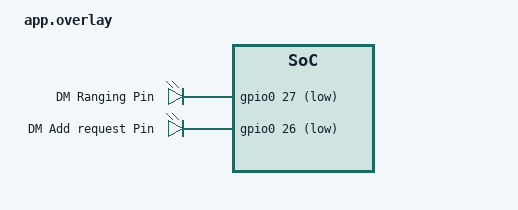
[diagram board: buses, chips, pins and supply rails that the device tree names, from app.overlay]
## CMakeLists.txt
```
#
# Copyright (c) 2021 Nordic Semiconductor
#
# SPDX-License-Identifier: LicenseRef-Nordic-5-Clause
#
cmake_minimum_required(VERSION 3.20)

find_package(Zephyr REQUIRED HINTS $ENV{ZEPHYR_BASE})
project(nrf_dm)

# NORDIC SDK APP START
target_sources(app PRIVATE
  src/main.c
  src/pwm_led.c
  src/peer.c
  src/service.c
  )
# NORDIC SDK APP END

zephyr_library_include_directories(${CMAKE_CURRENT_SOURCE_DIR})
```

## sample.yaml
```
sample:
  description: nRF Distance Measurement sample
  name: Distance measurement sample
common:
  tags:
    - bluetooth
    - ci_build
    - sysbuild
    - ci_samples_bluetooth
tests:
  sample.bluetooth.nrf_dm.timeslot:
    sysbuild: true
    build_only: true
    extra_configs:
      - CONFIG_DM_HIGH_PRECISION_CALC=n
    integration_platforms:
      - nrf5340dk/nrf5340/cpuapp
    platform_allow:
      - nrf5340dk/nrf5340/cpuapp
  sample.bluetooth.nrf_dm.timeslot.high_precision:
    sysbuild: true
    build_only: true
    extra_configs:
      - CONFIG_DM_HIGH_PRECISION_CALC=y
    integration_platforms:
      - nrf5340dk/nrf5340/cpuapp
    platform_allow:
      - nrf5340dk/nrf5340/cpuapp
```

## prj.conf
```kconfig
#
# Copyright (c) 2021 Nordic Semiconductor ASA
#
# SPDX-License-Identifier: LicenseRef-Nordic-5-Clause
#

# BT
CONFIG_BT=y

CONFIG_BT_CENTRAL=y
CONFIG_BT_PERIPHERAL=y

CONFIG_BT_SCAN=y
CONFIG_BT_SCAN_FILTER_ENABLE=y
CONFIG_BT_SCAN_NAME_CNT=1
CONFIG_BT_SCAN_MANUFACTURER_DATA_CNT=1
CONFIG_BT_SCAN_WITH_IDENTITY=y
CONFIG_BT_ID_MAX=1

CONFIG_BT_EXT_ADV=y

CONFIG_BT_DEVICE_NAME="nRF_DM"
CONFIG_BT_DDFS=y

# Distance Measurement
CONFIG_DM_MODULE=y

# Ineffective here: unsatisfied dependency HAS_MPSL_SUPPORT, so MPSL stays n.
# CONFIG_MPSL=y
CONFIG_MPSL_TIMESLOT_SESSION_COUNT=1

CONFIG_DM_MODULE_LOG_LEVEL_DBG=n
CONFIG_DM_GPIO_DEBUG=y
CONFIG_PWM=y

CONFIG_NCS_SAMPLES_DEFAULTS=y
CONFIG_DK_LIBRARY=y

CONFIG_DM_HIGH_PRECISION_CALC=y
```

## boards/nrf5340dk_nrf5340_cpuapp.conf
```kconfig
#
# Copyright (c) 2022 Nordic Semiconductor
#
# SPDX-License-Identifier: LicenseRef-Nordic-5-Clause
#

# Distance Measurement
CONFIG_DM_MODULE_RPC=y
CONFIG_DM_MODULE_RPC_CLIENT=y

CONFIG_TEST_RANDOM_GENERATOR=y

# NRF RPC
CONFIG_NRF_RPC_THREAD_POOL_SIZE=2

# SYSTEM WORKQUEUE
CONFIG_SYSTEM_WORKQUEUE_STACK_SIZE=3072
```

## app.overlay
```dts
/*
 * Copyright (c) 2023 Nordic Semiconductor ASA
 *
 * SPDX-License-Identifier: LicenseRef-Nordic-5-Clause
 */

/ {
	/* The timer instance to use. */
	chosen {
		ncs,dm-timer = &timer2;
	};

	/* The selected pins will be used by Distance Measurement module for debug purposes. */
	dm_gpio {
		compatible = "gpio-leds";

		dm_ranging: dm-ranging {
			gpios = <&gpio0 27 GPIO_ACTIVE_LOW>;
			label = "DM Ranging Pin";
		};

		dm_add_request: dm-add-request {
			gpios = <&gpio0 26 GPIO_ACTIVE_LOW>;
			label = "DM Add request Pin";
		};
	};
};
```

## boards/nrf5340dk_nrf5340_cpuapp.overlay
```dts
/*
 * Copyright (c) 2022 Nordic Semiconductor ASA
 *
 * SPDX-License-Identifier: LicenseRef-Nordic-5-Clause
 */

/* Enable pin forwarding to network core. The selected pins will be used by
 * Distance Measurement module for debug purposes.
 *
 * Note: Pay attention to assign the same GPIO pins as those provide in network core DTS overlay.
 */
&gpio_fwd {
	compatible = "nordic,nrf-gpio-forwarder";

	dm-gpio-if {
		gpios = <&gpio0 26 0>,
			<&gpio0 27 0>;
	};
};
```

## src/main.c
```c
/*
 * Copyright (c) 2021 Nordic Semiconductor ASA
 *
 * SPDX-License-Identifier: LicenseRef-Nordic-5-Clause
 */

/** @file
 *  @brief Nordic Distance Measurement sample
 */

#include <stdint.h>
#include <zephyr/kernel.h>
#include <zephyr/sys/printk.h>
#include <zephyr/sys/byteorder.h>

#include <zephyr/bluetooth/bluetooth.h>
#include <bluetooth/scan.h>
#include <bluetooth/services/ddfs.h>

#include <dk_buttons_and_leds.h>

#include <dm.h>
#include "peer.h"
#include "service.h"

#define DEVICE_NAME             CONFIG_BT_DEVICE_NAME
#define DEVICE_NAME_LEN         (sizeof(DEVICE_NAME) - 1)

#define RUN_STATUS_LED          DK_LED2
#define CON_STATUS_LED          DK_LED3
#define RUN_LED_BLINK_INTERVAL  1000

#define SUPPORT_DM_CODE         0xFF55AA5A

struct adv_mfg_data {
	uint16_t company_code;	    /* Company Identifier Code. */
	uint32_t support_dm_code;   /* To identify the device that supports distance measurement. */
	uint32_t rng_seed;          /* Random seed used for generating hopping patterns. */
} __packed;

static struct adv_mfg_data mfg_data;
struct bt_le_adv_param adv_param_conn =
	BT_LE_ADV_PARAM_INIT(BT_LE_ADV_OPT_CONN |
			     BT_LE_ADV_OPT_NOTIFY_SCAN_REQ,
			     BT_GAP_ADV_FAST_INT_MIN_2,
			     BT_GAP_ADV_FAST_INT_MAX_2,
			     NULL);

struct bt_le_adv_param adv_param_noconn =
	BT_LE_ADV_PARAM_INIT(BT_LE_ADV_OPT_USE_IDENTITY |
			     BT_LE_ADV_OPT_SCANNABLE |
			     BT_LE_ADV_OPT_NOTIFY_SCAN_REQ,
			     BT_GAP_ADV_FAST_INT_MIN_2,
			     BT_GAP_ADV_FAST_INT_MAX_2,
			     NULL);


struct bt_le_adv_param *adv_param = &adv_param_conn;

static const struct bt_data ad[] = {
	BT_DATA_BYTES(BT_DATA_FLAGS, (BT_LE_AD_GENERAL | BT_LE_AD_NO_BREDR)),
	BT_DATA(BT_DATA_NAME_COMPLETE, DEVICE_NAME, DEVICE_NAME_LEN),
};

static const struct bt_data sd[] = {
	BT_DATA(BT_DATA_MANUFACTURER_DATA, (unsigned char *)&mfg_data, sizeof(mfg_data)),
	BT_DATA_BYTES(BT_DATA_UUID128_ALL, BT_UUID_DDFS_VAL),
};

static struct bt_le_scan_param scan_param = {
	.type     = BT_LE_SCAN_TYPE_ACTIVE,
	.interval = BT_GAP_SCAN_FAST_INTERVAL,
	.window   = BT_GAP_SCAN_FAST_WINDOW,
	.options  = BT_LE_SCAN_OPT_NONE,
	.timeout  = 0,
};

static struct bt_scan_init_param scan_init = {
	.connect_if_match = 0,
	.scan_param = &scan_param,
	.conn_param = NULL
};

static uint32_t scanner_random_share;

static struct bt_le_ext_adv *adv;
static void adv_work_handle(struct k_work *item);
static K_WORK_DEFINE(adv_work, adv_work_handle);
static void adv_update_data(void);
static uint32_t scanner_addr_to_random_share(const bt_addr_t *p_scanner_addr);
static uint32_t get_id_addr_random_share(void);

static struct bt_scan_manufacturer_data scan_mfg_data = {
	.data = (unsigned char *)&mfg_data,
	.data_len = sizeof(mfg_data.company_code) + sizeof(mfg_data.support_dm_code),
};

static bool data_cb(struct bt_data *data, void *user_data)
{
	struct adv_mfg_data *recv_mfg_data;
	struct dm_request req;

	switch (data->type) {
	case BT_DATA_MANUFACTURER_DATA:
		if (sizeof(struct adv_mfg_data) == data->data_len) {
			recv_mfg_data = (struct adv_mfg_data *)data->data;

			bt_addr_le_copy(&req.bt_addr, user_data);
			req.role = DM_ROLE_INITIATOR;
			req.ranging_mode = peer_ranging_mode_get();
			/* We need to make sure that we only initiate a ranging to a single peer.
			 * A scan response that is received by this device can be received by
			 * multiple other devices which can all start a ranging at the same time
			 * as a consequence. To prevent this, we need to make sure that we set a
			 * per-peer random as the random seed. This helps the ranging library to
			 * avoid interference from other devices trying to range at the same time.
			 *
			 * This means that the initiator and the reflector need to set the same
			 * value for the random seed.
			 */
			req.rng_seed =
				sys_le32_to_cpu(recv_mfg_data->rng_seed) + scanner_random_share;
			req.start_delay_us = 0;
			req.extra_window_time_us = 0;

			dm_request_add(&req);
		}
		return false;
	default:
		return true;
	}
}

static uint32_t get_id_addr_random_share(void)
{
	bt_addr_le_t addrs[CONFIG_BT_ID_MAX];
	size_t count = CONFIG_BT_ID_MAX;

	bt_id_get(addrs, &count);

	__ASSERT(count == 1, "The sample assumes a single ID addr");

	return scanner_addr_to_random_share(&addrs[0].a);
}

static uint32_t scanner_addr_to_random_share(const bt_addr_t *p_scanner_addr)
{
	return (p_scanner_addr->val[0] | p_scanner_addr->val[1] << 8 |
		p_scanner_addr->val[2] << 16 | p_scanner_addr->val[3] << 24) +
	       (p_scanner_addr->val[4] | p_scanner_addr->val[5] << 8);
}

static void scan_filter_match(struct bt_scan_device_info *device_info,
			      struct bt_scan_filter_match *filter_match,
			      bool connectable)
{
	bt_addr_le_t addr;

	bt_addr_le_copy(&addr, device_info->recv_info->addr);
	peer_supported_add(device_info->recv_info->addr);
	bt_data_parse(device_info->adv_data, data_cb, &addr);
}

BT_SCAN_CB_INIT(scan_cb, scan_filter_match, NULL, NULL, NULL);

static void adv_scanned_cb(struct bt_le_ext_adv *adv,
			struct bt_le_ext_adv_scanned_info *info)
{
	struct dm_request req;

	if (peer_supported_test(info->addr)) {
		bt_addr_le_copy(&req.bt_addr, info->addr);
		req.role = DM_ROLE_REFLECTOR;
		req.ranging_mode = peer_ranging_mode_get();

		/* We need to make sure that we only initiate a ranging to a single peer.
		 * A scan response from this device can be received by multiple peers which can
		 * all start a ranging at the same time as a consequence. To prevent this,
		 * we need to make sure that we set a per-peer random as the random seed.
		 * This helps the ranging library to avoid interference from other devices
		 * trying to range at the same time.
		 *
		 * This means that the initiator and the reflector need to set the same value
		 * for the random seed.
		 */
		req.rng_seed = peer_rng_seed_get() + scanner_addr_to_random_share(&info->addr->a);
		req.start_delay_us = 0;
		req.extra_window_time_us = 0;

		dm_request_add(&req);
		adv_update_data();
	}
}

const static struct bt_le_ext_adv_cb adv_cb = {
	.scanned = adv_scanned_cb,
};

static void adv_update_data(void)
{
	int err;

	if (!adv) {
		return;
	}
	mfg_data.rng_seed = peer_rng_seed_prepare();
	err = bt_le_ext_adv_set_data(adv, ad, ARRAY_SIZE(ad), sd, ARRAY_SIZE(sd));
	if (err) {
		printk("Failed setting adv data (err %d)\n", err);
	}
}

static int adv_start(void)
{
	int err;
	struct bt_le_ext_adv_start_param ext_adv_start_param = {0};

	if (adv) {
		err = bt_le_ext_adv_stop(adv);
		if (err) {
			printk("Failed to stop extended advertising  (err %d)\n", err);
			return err;
		}
			err = bt_le_ext_adv_delete(adv);
		if (err) {
			printk("Failed to delete advertising set  (err %d)\n", err);
			return err;
		}
	}

	err = bt_le_ext_adv_create(adv_param, &adv_cb, &adv);
	if (err) {
		printk("Failed to create advertising set (err %d)\n", err);
		return err;
	}

	err = bt_le_ext_adv_set_data(adv, ad, ARRAY_SIZE(ad), sd, ARRAY_SIZE(sd));
	if (err) {
		printk("Failed setting adv data (err %d)\n", err);
		return err;
	}

	err = bt_le_ext_adv_start(adv, &ext_adv_start_param);
	if (err) {
		printk("Failed to start extended advertising  (err %d)\n", err);
		return err;
	}

	return err;
}

static int scan_start(void)
{
	int err;

	bt_scan_init(&scan_init);
	bt_scan_cb_register(&scan_cb);

	err = bt_scan_filter_add(BT_SCAN_FILTER_TYPE_MANUFACTURER_DATA, &scan_mfg_data);
	if (err) {
		printk("Scanning filters cannot be set (err %d)\n", err);
		return err;
	}

	err = bt_scan_filter_enable(BT_SCAN_MANUFACTURER_DATA_FILTER, false);
	if (err) {
		printk("Filters cannot be turned on (err %d)\n", err);
		return err;
	}

	scanner_random_share = get_id_addr_random_share();

	err = bt_scan_start(BT_SCAN_TYPE_SCAN_ACTIVE);
	if (err) {
		printk("Scanning failed to start (err %d)\n", err);
		return err;
	}

	return err;
}

static void adv_work_handle(struct k_work *item)
{
	adv_start();
}

static void connected(struct bt_conn *conn, uint8_t conn_err)
{
	adv_param = &adv_param_noconn;
	k_work_submit(&adv_work);

	dk_set_led_on(CON_STATUS_LED);
}

static void disconnected(struct bt_conn *conn, uint8_t reason)
{
	adv_param = &adv_param_conn;
	k_work_submit(&adv_work);

	dk_set_led_off(CON_STATUS_LED);
}

BT_CONN_CB_DEFINE(conn_callbacks) = {
	.connected = connected,
	.disconnected = disconnected,
};

static int bt_sync_init(void)
{
	/* Synchronisation is based on advertising and scanning modes.
	 * It occurs when SCAN_REQ and SCAN_RESP packets are exchanged.
	 */

	int err;

	printk("DM Bluetooth LE Synchronization initialization\n");

	mfg_data.company_code = sys_cpu_to_le16(CONFIG_BT_COMPANY_ID_NORDIC);
	mfg_data.support_dm_code = sys_cpu_to_le32(SUPPORT_DM_CODE);
	mfg_data.rng_seed = sys_cpu_to_le32(peer_rng_seed_prepare());

	err = adv_start();
	if (err) {
		printk("Failed to start advertising (err %d)\n", err);
		return err;
	}

	err = scan_start();
	if (err) {
		printk("Failed to start scanning (err %d)\n", err);
	}

	return err;
}

static void data_ready(struct dm_result *result)
{
	if (result->status) {
		peer_update(result);
	}
}

static struct dm_cb dm_cb = {
	.data_ready = data_ready,
};

int main(void)
{
	int err;
	uint32_t blink_status = 0;
	struct dm_init_param init_param;

	printk("Starting Distance Measurement sample\n");

	err = dk_leds_init();
	if (err) {
		printk("LEDs init failed (err %d)\n", err);
		return 0;
	}

	err = peer_init();
	if (err) {
		printk("Peer init failed (err %d)\n", err);
		return 0;
	}

	init_param.cb = &dm_cb;

	err = dm_init(&init_param);
	if (err) {
		printk("Distance measurement init failed (err %d)\n", err);
		return 0;
	}

	err = service_ddfs_init();
	if (err) {
		printk("DDF Service init failed (err %d)\n", err);
		return 0;
	}

	err = bt_enable(NULL);
	if (err) {
		printk("Bluetooth init failed (err %d)\n", err);
		return 0;
	}

	err = bt_sync_init();
	if (err) {
		printk("Synchronisation init failed (err %d)\n", err);
		return 0;
	}

	for (;;) {
		dk_set_led(RUN_STATUS_LED, (++blink_status) % 2);
		k_sleep(K_MSEC(RUN_LED_BLINK_INTERVAL));
		service_azimuth_elevation_simulation();
	}
}
```

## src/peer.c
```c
/*
 * Copyright (c) 2021 Nordic Semiconductor ASA
 *
 * SPDX-License-Identifier: LicenseRef-Nordic-5-Clause
 */

#include <zephyr/kernel.h>
#include <zephyr/random/random.h>

#include <math.h>

#include "peer.h"
#include "pwm_led.h"
#include "service.h"

#define PEER_MAX                8   /* Maximum number of tracked peer devices. */

#define STACKSIZE               1024
#define PEER_THREAD_PRIORITY    K_LOWEST_APPLICATION_THREAD_PRIO

#define PEER_TIMEOUT_STEP_MS    500
#define PEER_TIMEOUT_INIT_MS    10000

#define DISTANCE_MAX_LED        50   /* from 0 to DISTANCE_MAX_LED [decimeter] -
				      * the distance range which is indicated by the PWM LED
				      */
#define DEFAULT_RANGING_MODE    DM_RANGING_MODE_MCPD

static void timeout_handler(struct k_timer *timer_id);
static K_TIMER_DEFINE(timer, timeout_handler, NULL);

struct peer_entry {
	sys_snode_t node;
	bt_addr_le_t bt_addr;
	struct dm_result result;
	uint16_t timeout_ms;
};

static struct peer_entry *closest_peer;
static uint32_t rng_seed;
static enum dm_ranging_mode ranging_mode = DEFAULT_RANGING_MODE;

K_MSGQ_DEFINE(result_msgq, sizeof(struct dm_result), 16, 4);

static K_HEAP_DEFINE(peer_heap, PEER_MAX * sizeof(struct peer_entry));
static sys_slist_t peer_list = SYS_SLIST_STATIC_INIT(&peer_list);

static K_MUTEX_DEFINE(list_mtx);

static void list_lock(void)
{
	k_mutex_lock(&list_mtx, K_FOREVER);
}

static void list_unlock(void)
{
	k_mutex_unlock(&list_mtx);
}

static struct peer_entry *mcpd_min_peer_result(struct peer_entry *a, struct peer_entry *b)
{
	if (!a && !b) {
		return NULL;
	} else if (!a && b) {
		return b->result.ranging_mode == DM_RANGING_MODE_MCPD ? b : NULL;
	} else if (a && !b) {
		return a->result.ranging_mode == DM_RANGING_MODE_MCPD ? a : NULL;
	} else if (a->result.ranging_mode == DM_RANGING_MODE_RTT &&
		   b->result.ranging_mode == DM_RANGING_MODE_RTT) {
		return NULL;
	} else if (a->result.ranging_mode == DM_RANGING_MODE_RTT &&
		   b->result.ranging_mode == DM_RANGING_MODE_MCPD) {
		return b;
	} else if (a->result.ranging_mode == DM_RANGING_MODE_MCPD &&
		   b->result.ranging_mode == DM_RANGING_MODE_RTT){
		return a;
	}

#ifdef CONFIG_DM_HIGH_PRECISION_CALC
	float dist_a = !isnan(a->result.dist_estimates.mcpd.high_precision) ?
		  a->result.dist_estimates.mcpd.high_precision : a->result.dist_estimates.mcpd.best;
	float dist_b = !isnan(b->result.dist_estimates.mcpd.high_precision) ?
		  b->result.dist_estimates.mcpd.high_precision : b->result.dist_estimates.mcpd.best;

	if (dist_a < dist_b) {
		return a;
	}
	return b;
#else
	if (a->result.dist_estimates.mcpd.best < b->result.dist_estimates.mcpd.best) {
		return a;
	}
	return b;
#endif
}

static struct peer_entry *peer_find_closest(void)
{
	struct peer_entry *closest_peer, *item;
	sys_snode_t *node, *tmp;

	closest_peer = SYS_SLIST_PEEK_HEAD_CONTAINER(&peer_list, closest_peer, node);
	if (!closest_peer) {
		return NULL;
	}

	SYS_SLIST_FOR_EACH_NODE_SAFE(&peer_list, node, tmp) {
		item = CONTAINER_OF(node, struct peer_entry, node);
		closest_peer = mcpd_min_peer_result(closest_peer, item);
	}

	return closest_peer;
}

struct peer_entry *peer_find(const bt_addr_le_t *peer)
{
	if (!peer) {
		return NULL;
	}

	sys_snode_t *node, *tmp;
	struct peer_entry *item;

	SYS_SLIST_FOR_EACH_NODE_SAFE(&peer_list, node, tmp) {
		item = CONTAINER_OF(node, struct peer_entry, node);
		if (bt_addr_le_cmp(&item->bt_addr, peer) == 0) {
			return item;
		}
	}

	return NULL;
}

static void ble_notification(const struct peer_entry *peer)
{
	service_distance_measurement_update(&peer->bt_addr, &peer->result);
}

static void led_notification(const struct peer_entry *peer)
{
	if (!peer) {
		pwm_led_set(0);
		return;
	}

	float res;

	if (peer->result.ranging_mode == DM_RANGING_MODE_RTT) {
		res = peer->result.dist_estimates.rtt.rtt;
	} else {
#ifdef CONFIG_DM_HIGH_PRECISION_CALC
		res = peer->result.dist_estimates.mcpd.high_precision;
		res = isnan(res) ? peer->result.dist_estimates.mcpd.best : res;
#else
		res = peer->result.dist_estimates.mcpd.best;
#endif
	}

	res = (res < 0 ? 0 : res) * 10;
	if (res > DISTANCE_MAX_LED) {
		pwm_led_set(0);
	} else {
		pwm_led_set((UINT16_MAX/DISTANCE_MAX_LED * res * (-1)) + UINT16_MAX);
	}
}

static void print_result(struct dm_result *result)
{
	if (!result) {
		return;
	}

	const char *quality[DM_QUALITY_NONE + 1] = {"ok", "poor", "do not use", "crc fail", "none"};
	char addr[BT_ADDR_LE_STR_LEN];

	bt_addr_le_to_str(&result->bt_addr, addr, sizeof(addr));

	printk("\nMeasurement result:\n");
	printk("\tAddr: %s\n", addr);
	printk("\tQuality: %s\n", quality[result->quality]);

	printk("\tDistance estimates: ");
	if (result->ranging_mode == DM_RANGING_MODE_RTT) {
		printk("rtt: rtt=%.2f\n", (double)result->dist_estimates.rtt.rtt);
	} else {
#ifdef CONFIG_DM_HIGH_PRECISION_CALC
		printk("mcpd: high_precision=%.2f ifft=%.2f phase_slope=%.2f "
			"rssi_openspace=%.2f best=%.2f\n",
			(double)result->dist_estimates.mcpd.high_precision,
			(double)result->dist_estimates.mcpd.ifft,
			(double)result->dist_estimates.mcpd.phase_slope,
			(double)result->dist_estimates.mcpd.rssi_openspace,
			(double)result->dist_estimates.mcpd.best);
#else
		printk("mcpd: ifft=%.2f phase_slope=%.2f rssi_openspace=%.2f best=%.2f\n",
			(double)result->dist_estimates.mcpd.ifft,
			(double)result->dist_estimates.mcpd.phase_slope,
			(double)result->dist_estimates.mcpd.rssi_openspace,
			(double)result->dist_estimates.mcpd.best);
#endif
	}
}

static void timeout_handler(struct k_timer *timer_id)
{
	sys_snode_t *node, *tmp;
	struct peer_entry *item;

	SYS_SLIST_FOR_EACH_NODE_SAFE(&peer_list, node, tmp) {
		item = CONTAINER_OF(node, struct peer_entry, node);
		if (item->timeout_ms > PEER_TIMEOUT_STEP_MS) {
			item->timeout_ms -= PEER_TIMEOUT_STEP_MS;
		} else {
			sys_slist_remove(&peer_list, NULL, node);
			k_heap_free(&peer_heap, item);
			closest_peer = peer_find_closest();

			led_notification(closest_peer);
		}
	}
}

static void peer_thread(void)
{
	struct dm_result result;

	while (1) {
		if (k_msgq_get(&result_msgq, &result, K_FOREVER) == 0) {
			struct peer_entry *peer;

			peer = peer_find(&result.bt_addr);
			if (!peer) {
				continue;
			}

			memcpy(&peer->result, &result, sizeof(peer->result));
			peer->timeout_ms = PEER_TIMEOUT_INIT_MS;
			print_result(&peer->result);

			closest_peer = mcpd_min_peer_result(closest_peer, peer);

			led_notification(closest_peer);
			ble_notification(peer);
		}
	}
}

void peer_ranging_mode_set(enum dm_ranging_mode mode)
{
	ranging_mode = mode;
}

enum dm_ranging_mode peer_ranging_mode_get(void)
{
	return ranging_mode;
}

uint32_t peer_rng_seed_prepare(void)
{
	rng_seed = sys_rand32_get();
	return rng_seed;
}

uint32_t peer_rng_seed_get(void)
{
	return rng_seed;
}

bool peer_supported_test(const bt_addr_le_t *peer)
{
	sys_snode_t *node, *tmp;
	struct peer_entry *item;

	SYS_SLIST_FOR_EACH_NODE_SAFE(&peer_list, node, tmp) {
		item = CONTAINER_OF(node, struct peer_entry, node);
		if (bt_addr_le_cmp(&item->bt_addr, peer) == 0) {
			return true;
		}
	}

	return false;
}

int peer_supported_add(const bt_addr_le_t *peer)
{
	struct peer_entry *item;

	if (peer_supported_test(peer)) {
		return 0;
	}

	item = k_heap_alloc(&peer_heap, sizeof(struct peer_entry), K_NO_WAIT);
	if (!item) {
		return -ENOMEM;
	}

	item->timeout_ms = PEER_TIMEOUT_INIT_MS;
	bt_addr_le_copy(&item->bt_addr, peer);
	list_lock();
	sys_slist_append(&peer_list, &item->node);
	list_unlock();

	return 0;
}

void peer_update(struct dm_result *result)
{
	k_msgq_put(&result_msgq, result, K_NO_WAIT);
}

int peer_init(void)
{
	int err;

	k_timer_start(&timer, K_NO_WAIT, K_MSEC(PEER_TIMEOUT_STEP_MS));

	err = pwm_led_init();
	if (err) {
		printk("PWM LED init failed (err %d)\n", err);
		return err;
	}

	return 0;
}

K_THREAD_DEFINE(peer_consumer_thred_id, STACKSIZE, peer_thread,
		NULL, NULL, NULL, PEER_THREAD_PRIORITY, 0, 0);
```

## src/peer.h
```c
/*
 * Copyright (c) 2021 Nordic Semiconductor ASA
 *
 * SPDX-License-Identifier: LicenseRef-Nordic-5-Clause
 */

#ifndef PEER_H_
#define PEER_H_

#ifdef __cplusplus
extern "C" {
#endif

#include <zephyr/kernel.h>
#include <zephyr/bluetooth/addr.h>
#include <dm.h>

/** @brief Testing if the peer is supported.
 *
 *  @param peer Bluetooth LE Device Address.
 *
 *  @retval /a true peer is supported.
 *          /a false peer is not supported.
 */
bool peer_supported_test(const bt_addr_le_t *peer);

/** @brief Add a new supported peer.
 *
 *  @param peer Bluetooth LE Device Address.
 *
 *  @retval 0 if the operation was successful, otherwise a (negative) error code.
 */
int peer_supported_add(const bt_addr_le_t *peer);

/** @brief Set a new Distance Measurement ranging mode.
 *
 *  @param mode Ranging mode.
 */
void peer_ranging_mode_set(enum dm_ranging_mode mode);

/** @brief Get the current ranging mode.
 *
 *  @param None
 *
 *  @retval Ranging mode value.
 */
enum dm_ranging_mode peer_ranging_mode_get(void);

/** @brief Prepare and get a random seed.
 *
 *  @retval Random seed value.
 */
uint32_t peer_rng_seed_prepare(void);

/** @brief Get the current random seed.
 *
 *  @retval Random seed value.
 */
uint32_t peer_rng_seed_get(void);

/** @brief Initialize the peer management module.
 *
 *  @param None
 *
 *  @retval 0 if the operation was successful, otherwise a (negative) error code.
 */
int peer_init(void);

/** @brief Peer measurement update.
 *
 *  @param result Measurement structure.
 */
void peer_update(struct dm_result *result);


#ifdef __cplusplus
}
#endif

#endif /* PEER_H_ */
```

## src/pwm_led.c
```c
/*
 * Copyright (c) 2021 Nordic Semiconductor ASA
 *
 * SPDX-License-Identifier: LicenseRef-Nordic-5-Clause
 */

#include "pwm_led.h"
#include <nrfx.h>
#include <nrfx_gpiote.h>
#include <zephyr/drivers/pwm.h>

#define PWM_LED0_NODE	DT_ALIAS(pwm_led0)

#if DT_NODE_HAS_STATUS(PWM_LED0_NODE, okay)
static const struct pwm_dt_spec led0 = PWM_DT_SPEC_GET(PWM_LED0_NODE);
#else
#error "Unsupported board: pwm-led0 devicetree alias is not defined"
#endif

#define PWM_PERIOD	1024
#define LIGHTNESS_MAX	UINT16_MAX

int pwm_led_init(void)
{
	if (!device_is_ready(led0.dev)) {
		return -1;
	}

	return 0;
}

void pwm_led_set(uint16_t desired_lvl)
{
	uint32_t scaled_lvl = (PWM_PERIOD * desired_lvl) / LIGHTNESS_MAX;

	pwm_set_dt(&led0, PWM_USEC(PWM_PERIOD), PWM_USEC(scaled_lvl));
}
```

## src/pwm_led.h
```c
/*
 * Copyright (c) 2021 Nordic Semiconductor ASA
 *
 * SPDX-License-Identifier: LicenseRef-Nordic-5-Clause
 */

#ifndef PWM_LED_H_
#define PWM_LED_H_

#include <zephyr/kernel.h>
#include <stdlib.h>
#include <zephyr/types.h>

#ifdef __cplusplus
extern "C" {
#endif

/** @brief Initialize the PWM LED.
 *
 *  @param None
 *
 *  @retval 0 if the operation was successful, otherwise a (negative) error code.
 */
int pwm_led_init(void);

/** @brief Set the PWM level.
 *
 *  @param desired_lvl Level value.
 */
void pwm_led_set(uint16_t desired_lvl);

#ifdef __cplusplus
}
#endif

#endif /* PWM_LED_H_ */
```

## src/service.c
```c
/*
 * Copyright (c) 2021 Nordic Semiconductor ASA
 *
 * SPDX-License-Identifier: LicenseRef-Nordic-5-Clause
 */

#include <zephyr/kernel.h>
#include <bluetooth/services/ddfs.h>
#include <zephyr/random/random.h>
#include <dm.h>

#include "service.h"
#include "peer.h"


static int dm_ranging_mode_set(uint8_t mode)
{
	if (mode == BT_DDFS_DM_RANGING_MODE_RTT) {
		peer_ranging_mode_set(DM_RANGING_MODE_RTT);
	} else if (mode == BT_DDFS_DM_RANGING_MODE_MCPD) {
		peer_ranging_mode_set(DM_RANGING_MODE_MCPD);
	} else {
		return -1;
	}

	printk("DM set ranging mode to %s\n", mode == BT_DDFS_DM_RANGING_MODE_RTT ? "RTT" : "MCPD");
	return 0;
}

static int dm_config_read(struct bt_ddfs_dm_config *config)
{
	enum dm_ranging_mode ranging_mode;

	if (!config) {
		return -1;
	}

	ranging_mode = peer_ranging_mode_get();
	if (ranging_mode == DM_RANGING_MODE_RTT) {
		config->mode = BT_DDFS_DM_RANGING_MODE_RTT;
	} else if (ranging_mode == DM_RANGING_MODE_MCPD) {
		config->mode = BT_DDFS_DM_RANGING_MODE_MCPD;
	} else {
		return -1;
	}

	if (IS_ENABLED(CONFIG_DM_HIGH_PRECISION_CALC)) {
		config->high_precision = true;
	} else {
		config->high_precision = false;
	}

	return 0;
}

static uint16_t meter_to_decimeter(float value)
{
	float val;

	val = (value < 0 ? 0 : value) * 10;
	return val < UINT16_MAX ? (uint16_t)val : UINT16_MAX;
}

void service_distance_measurement_update(const bt_addr_le_t *addr, const struct dm_result *result)
{
	struct bt_ddfs_distance_measurement measurement;
	int err;

	if (!addr || !result) {
		return;
	}

	if (result->quality == DM_QUALITY_OK) {
		measurement.quality = BT_DDFS_QUALITY_OK;
	} else if (result->quality == DM_QUALITY_POOR) {
		measurement.quality = BT_DDFS_QUALITY_POOR;
	} else if (result->quality == DM_QUALITY_DO_NOT_USE) {
		measurement.quality = BT_DDFS_QUALITY_DO_NOT_USE;
	} else if (result->quality == DM_QUALITY_CRC_FAIL) {
		measurement.quality = BT_DDFS_QUALITY_DO_NOT_USE;
	} else {
		measurement.quality = BT_DDFS_QUALITY_NONE;
	}

	if (result->ranging_mode == DM_RANGING_MODE_RTT) {
		measurement.ranging_mode = BT_DDFS_DM_RANGING_MODE_RTT;
		measurement.dist_estimates.rtt.rtt =
				meter_to_decimeter(result->dist_estimates.rtt.rtt);
	} else {
		measurement.ranging_mode = BT_DDFS_DM_RANGING_MODE_MCPD;
		measurement.dist_estimates.mcpd.ifft =
				meter_to_decimeter(result->dist_estimates.mcpd.ifft);
		measurement.dist_estimates.mcpd.phase_slope =
				meter_to_decimeter(result->dist_estimates.mcpd.phase_slope);
		measurement.dist_estimates.mcpd.rssi_openspace =
				meter_to_decimeter(result->dist_estimates.mcpd.rssi_openspace);
		measurement.dist_estimates.mcpd.best =
				meter_to_decimeter(result->dist_estimates.mcpd.best);
#ifdef CONFIG_DM_HIGH_PRECISION_CALC
		measurement.dist_estimates.mcpd.high_precision =
				meter_to_decimeter(result->dist_estimates.mcpd.high_precision);
#endif
	}

	bt_addr_le_copy(&measurement.bt_addr, addr);

	err = bt_ddfs_distance_measurement_notify(NULL, &measurement);
	if (err && (err != -EACCES) && (err != -ENOTCONN)) {
		printk("Failed to send distance measurement (err %d)\n", err);
	}
}

void service_azimuth_elevation_simulation(void)
{
	int err;

	uint32_t rand = sys_rand32_get();
	struct bt_ddfs_elevation_measurement elevation;
	struct bt_ddfs_azimuth_measurement azimuth;
	const bt_addr_le_t bt_addr = {
		.type = BT_ADDR_LE_RANDOM,
		.a.val = {0xFF, 0xEE, 0xDD, 0xCC, 0xBB, 0xAA},
	};

	elevation.quality = rand % (BT_DDFS_QUALITY_DO_NOT_USE + 1);
	elevation.value	= -90 + rand % 91;
	bt_addr_le_copy(&elevation.bt_addr, &bt_addr);

	azimuth.quality = rand % (BT_DDFS_QUALITY_DO_NOT_USE + 1);
	azimuth.value = rand % 360;
	bt_addr_le_copy(&azimuth.bt_addr, &bt_addr);

	err = bt_ddfs_elevation_measurement_notify(NULL, &elevation);
	if (err && (err != -EACCES) && (err != -ENOTCONN)) {
		printk("Failed to send elevation measurement (err %d)\n", err);
	}

	err = bt_ddfs_azimuth_measurement_notify(NULL, &azimuth);
	if (err && (err != -EACCES) && (err != -ENOTCONN)) {
		printk("Failed to send azimuth measurement (err %d)\n", err);
	}
}

static const struct bt_ddfs_cb cb = {
	.dm_ranging_mode_set = dm_ranging_mode_set,
	.dm_config_read = dm_config_read,
	.am_notification_config_changed = NULL,
	.dm_notification_config_changed = NULL,
	.em_notification_config_changed = NULL
};

int service_ddfs_init(void)
{
	struct bt_ddfs_init_params ddfs_init = {0};

	ddfs_init.dm_features.ranging_mode_rtt = 1;
	ddfs_init.dm_features.ranging_mode_mcpd = 1;
	ddfs_init.cb = &cb;

	return bt_ddfs_init(&ddfs_init);
}
```

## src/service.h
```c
/*
 * Copyright (c) 2022 Nordic Semiconductor ASA
 *
 * SPDX-License-Identifier: LicenseRef-Nordic-5-Clause
 */

#ifndef SERVICE_H_
#define SERVICE_H_

#ifdef __cplusplus
extern "C" {
#endif

#include <zephyr/kernel.h>
#include <dm.h>

/** @brief Distance Measurement update result.
 *
 *  @param addr Bluetooth LE Device Address.
 *
 *  @param result Measurement structure.
 */
void service_distance_measurement_update(const bt_addr_le_t *addr, const struct dm_result *result);

/** @brief Simulation of azimuth and elevation measurements.
 *
 *  @param None
 */
void service_azimuth_elevation_simulation(void);

/** @brief Initialize the Direction and Distance Finding Service.
 *
 *  @param None
 *
 *  @retval 0 if the operation was successful, otherwise a (negative) error code.
 */
int service_ddfs_init(void);

#ifdef __cplusplus
}
#endif

#endif /* SERVICE_H_ */
```
